# nrf54lilium_network register map
Vendor: Nordic Semiconductor; Series: nrf54; File version: 1
CPU: CM33 r0p4, little endian, MPU, no FPU, 3 interrupt priority bits, 30 interrupts
Registers are 32-bit, read-write, reset 0x0 unless marked. A register's access mark holds for its fields unless they carry their own. Offsets are from the block's base; [hi:lo] are bit positions; {n}, {i} and the like mark numbered series; 'fields as' and 'values as' point back to an identical list.

## RADIO (part 2 of 3) — 2.4 GHz radio 2.4 GHz radio
Base 0x41008000
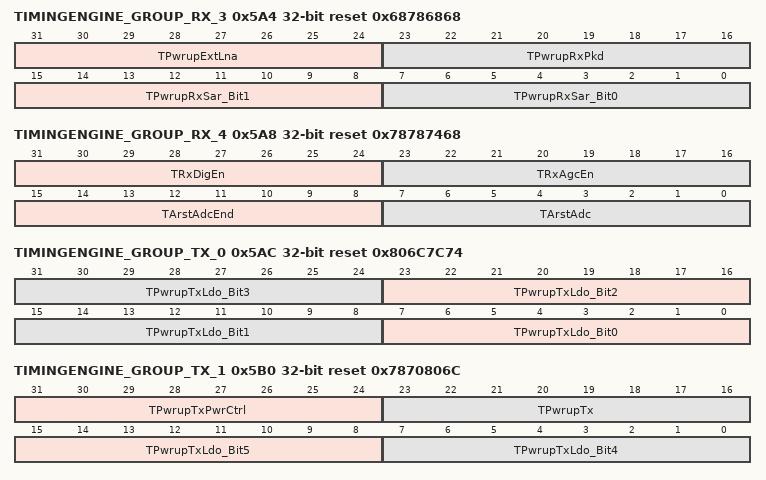
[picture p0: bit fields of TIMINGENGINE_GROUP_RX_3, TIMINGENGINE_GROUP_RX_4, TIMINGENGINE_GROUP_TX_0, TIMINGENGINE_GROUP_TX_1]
0x5A4 TIMINGENGINE_GROUP_RX_3 reset 0x68786868 — TODO
  [31:24] TPwrupExtLna — (unit: 0.25us) Timing control of PwrupExtLna
  [23:16] TPwrupRxPkd — Spare register. Power up peak detector is now tied with power up mixer.
  [15:8] TPwrupRxSar_Bit1 — (unit: 0.25us) Timing control of PwrupRxSar[1]
  [7:0] TPwrupRxSar_Bit0 — (unit: 0.25us) Timing control of PwrupRxSar[0]
0x5A8 TIMINGENGINE_GROUP_RX_4 reset 0x78787468 — TODO
  [31:24] TRxDigEn — (unit: 0.25us) Timing control of RxDigEn
  [23:16] TRxAgcEn — (unit: 0.25us) Timing control of RxAgcEn
  [15:8] TArstAdcEnd — (unit: 0.25us) Timing control of ArstAdcEnd
  [7:0] TArstAdc — (unit: 0.25us) Timing control of ArstAdc
0x5AC TIMINGENGINE_GROUP_TX_0 reset 0x806C7C74 — TODO
  [8n+7:8n] TPwrupTxLdo_Bit{n} (n=0..3) — (unit: 0.25us) Timing control of PwrupTxLdo[{n}]
0x5B0 TIMINGENGINE_GROUP_TX_1 reset 0x7870806C — TODO
  [31:24] TPwrupTxPwrCtrl — (unit: 0.25us) Timing control of PwrupTxPwrCtrl
  [23:16] TPwrupTx — (unit: 0.25us) Timing control of PwrupTx
  [15:8] TPwrupTxLdo_Bit5 — (unit: 0.25us) Timing control of PwrupTxLdo[5]
  [7:0] TPwrupTxLdo_Bit4 — (unit: 0.25us) Timing control of PwrupTxLdo[4]
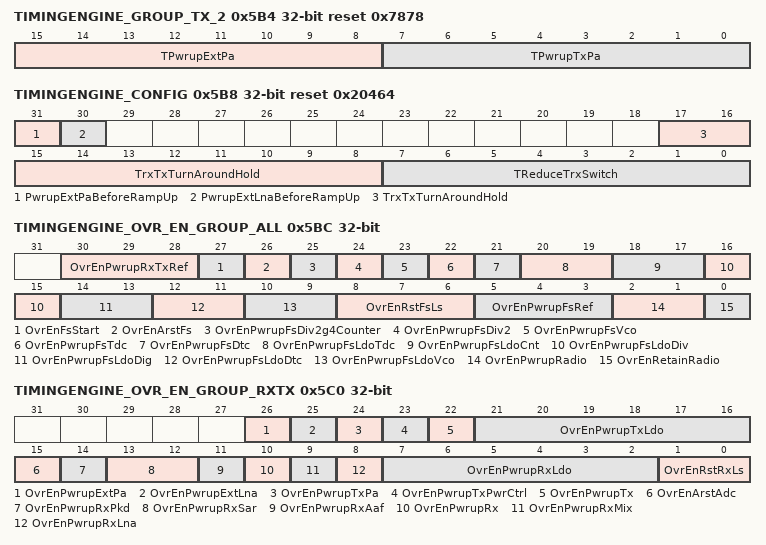
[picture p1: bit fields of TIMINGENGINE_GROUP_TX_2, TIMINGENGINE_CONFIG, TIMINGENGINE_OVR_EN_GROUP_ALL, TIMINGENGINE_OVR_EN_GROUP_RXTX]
0x5B4 TIMINGENGINE_GROUP_TX_2 reset 0x7878 — TODO
  [15:8] TPwrupExtPa — (unit: 0.25us) Timing control of PwrupExtPa
  [7:0] TPwrupTxPa — (unit: 0.25us) Timing control of PwrupTxPa
0x5B8 TIMINGENGINE_CONFIG reset 0x20464 — TODO
  [31] PwrupExtPaBeforeRampUp — In legacy timing mode, pwrupExtPa can be powered on before starting to ramp up by setting this registers to 1.
  [30] PwrupExtLnaBeforeRampUp — In legacy timing mode, pwrupExtLna can be powered on before starting to ramp up by setting this registers to 1.
  [17:8] TrxTxTurnAroundHold — (unit: 0.25us) Additional delay to hold Tx/Rx turnaround
  [7:0] TReduceTrxSwitch — (unit: 0.25us) Reduced timing for on-the-fly switch on both Rx->Tx and Tx->Rx
0x5BC TIMINGENGINE_OVR_EN_GROUP_ALL — TODO
  [30:28] OvrEnPwrupRxTxRef — Override enable of PwrupRxTxRef
  [27] OvrEnFsStart — Override enable of FsStart
  [26] OvrEnArstFs — Override enable of ArstFs
  [25] OvrEnPwrupFsDiv2g4Counter — Override enable of PwrupFsDiv2g4Counter
  [24] OvrEnPwrupFsDiv2 — Override enable of PwrupFsDiv2
  [23] OvrEnPwrupFsVco — Override enable of PwrupFsVco
  [22] OvrEnPwrupFsTdc — Override enable of PwrupFsTdc
  [21] OvrEnPwrupFsDtc — Override enable of PwrupFsDtc
  [20:19] OvrEnPwrupFsLdoTdc — Override enable of PwrupFsLdoTdc
  [18:17] OvrEnPwrupFsLdoCnt — Override enable of PwrupFsLdoCnt
  [16:15] OvrEnPwrupFsLdoDiv — Override enable of PwrupFsLdoDiv
  [14:13] OvrEnPwrupFsLdoDig — Override enable of PwrupFsLdoDig
  [12:11] OvrEnPwrupFsLdoDtc — Override enable of PwrupFsLdoDtc
  [10:9] OvrEnPwrupFsLdoVco — Override enable of PwrupFsLdoVco
  [8:6] OvrEnRstFsLs — Override enable of RstFsLs
  [5:3] OvrEnPwrupFsRef — Override enable of PwrupFsRef
  [2:1] OvrEnPwrupRadio — Override enable of PwrupRadio
  [0] OvrEnRetainRadio — Override enable of RetainRadio
0x5C0 TIMINGENGINE_OVR_EN_GROUP_RXTX — TODO
  [26] OvrEnPwrupExtPa — Override enable of PwrupExtPa
  [25] OvrEnPwrupExtLna — Override enable of PwrupExtLna
  [24] OvrEnPwrupTxPa — Override enable of PwrupTxPa
  [23] OvrEnPwrupTxPwrCtrl — Override enable of PwrupTxPwrCtrl
  [22] OvrEnPwrupTx — Override enable of PwrupTx
  [21:16] OvrEnPwrupTxLdo — Override enable of PwrupTxLdo
  [15] OvrEnArstAdc — Override enable of ArstAdc
  [14] OvrEnPwrupRxPkd — Override enable of PwrupRxPkd
  [13:12] OvrEnPwrupRxSar — Override enable of PwrupRxSar
  [11] OvrEnPwrupRxAaf — Override enable of PwrupRxAaf
  [10] OvrEnPwrupRx — Override enable of PwrupRx
  [9] OvrEnPwrupRxMix — Override enable of PwrupRxMix
  [8] OvrEnPwrupRxLna — Override enable of PwrupRxLna
  [7:2] OvrEnPwrupRxLdo — Override enable of PwrupRxLdo
  [1:0] OvrEnRstRxLs — Override enable of RstRxLs
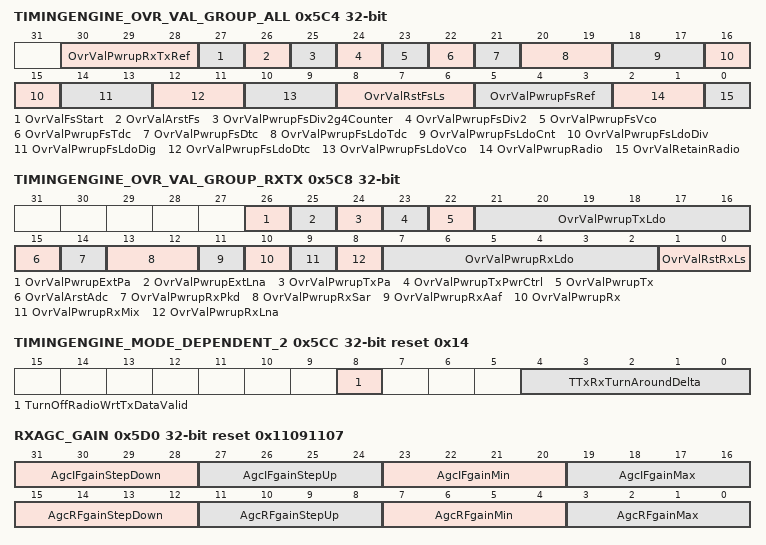
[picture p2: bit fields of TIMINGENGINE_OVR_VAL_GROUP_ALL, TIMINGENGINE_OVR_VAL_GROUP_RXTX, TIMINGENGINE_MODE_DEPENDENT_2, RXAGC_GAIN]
0x5C4 TIMINGENGINE_OVR_VAL_GROUP_ALL — TODO
  [30:28] OvrValPwrupRxTxRef — Override value of PwrupRxTxRef
  [27] OvrValFsStart — Override value of FsStart
  [26] OvrValArstFs — Override value of ArstFs
  [25] OvrValPwrupFsDiv2g4Counter — Override value of PwrupFsDiv2g4Counter
  [24] OvrValPwrupFsDiv2 — Override value of PwrupFsDiv2
  [23] OvrValPwrupFsVco — Override value of PwrupFsVco
  [22] OvrValPwrupFsTdc — Override value of PwrupFsTdc
  [21] OvrValPwrupFsDtc — Override value of PwrupFsDtc
  [20:19] OvrValPwrupFsLdoTdc — Override value of PwrupFsLdoTdc
  [18:17] OvrValPwrupFsLdoCnt — Override value of PwrupFsLdoCnt
  [16:15] OvrValPwrupFsLdoDiv — Override value of PwrupFsLdoDiv
  [14:13] OvrValPwrupFsLdoDig — Override value of PwrupFsLdoDig
  [12:11] OvrValPwrupFsLdoDtc — Override value of PwrupFsLdoDtc
  [10:9] OvrValPwrupFsLdoVco — Override value of PwrupFsLdoVco
  [8:6] OvrValRstFsLs — Override value of RstFsLs
  [5:3] OvrValPwrupFsRef — Override value of PwrupFsRef
  [2:1] OvrValPwrupRadio — Override value of PwrupRadio
  [0] OvrValRetainRadio — Override value of RetainRadio
0x5C8 TIMINGENGINE_OVR_VAL_GROUP_RXTX — TODO
  [26] OvrValPwrupExtPa — Override value of PwrupExtPa
  [25] OvrValPwrupExtLna — Override value of PwrupExtLna
  [24] OvrValPwrupTxPa — Override value of PwrupTxPa
  [23] OvrValPwrupTxPwrCtrl — Override value of PwrupTxPwrCtrl
  [22] OvrValPwrupTx — Override value of PwrupTx
  [21:16] OvrValPwrupTxLdo — Override value of PwrupTxLdo
  [15] OvrValArstAdc — Override value of ArstAdc
  [14] OvrValPwrupRxPkd — Override value of PwrupRxPkd
  [13:12] OvrValPwrupRxSar — Override value of PwrupRxSar
  [11] OvrValPwrupRxAaf — Override value of PwrupRxAaf
  [10] OvrValPwrupRx — Override value of PwrupRx
  [9] OvrValPwrupRxMix — Override value of PwrupRxMix
  [8] OvrValPwrupRxLna — Override value of PwrupRxLna
  [7:2] OvrValPwrupRxLdo — Override value of PwrupRxLdo
  [1:0] OvrValRstRxLs — Override value of RstRxLs
0x5CC TIMINGENGINE_MODE_DEPENDENT_2 reset 0x14 — TODO
  [8] TurnOffRadioWrtTxDataValid — Turn off radio w.r.t txDataValid in addition to radioEn
  [4:0] TTxRxTurnAroundDelta — Additional offset in Rx mode, for Rx to be able to be ready earlier, which is required for 2Mbps.
0x5D0 RXAGC_GAIN reset 0x11091107 — TODO
  [31:28] AgcIFgainStepDown — gain step for decreasing IF gain
  [27:24] AgcIFgainStepUp — gain step for increasing IF gain
  [23:20] AgcIFgainMin — Minimum gain of IF gain
  [19:16] AgcIFgainMax — Maximum gain of IF gain
  [15:12] AgcRFgainStepDown — gain step for decreasing RF gain
  [11:8] AgcRFgainStepUp — gain step for increasing RF gain
  [7:4] AgcRFgainMin — Minimum gain of RF gain
  [3:0] AgcRFgainMax — Maximum gain of RF gain
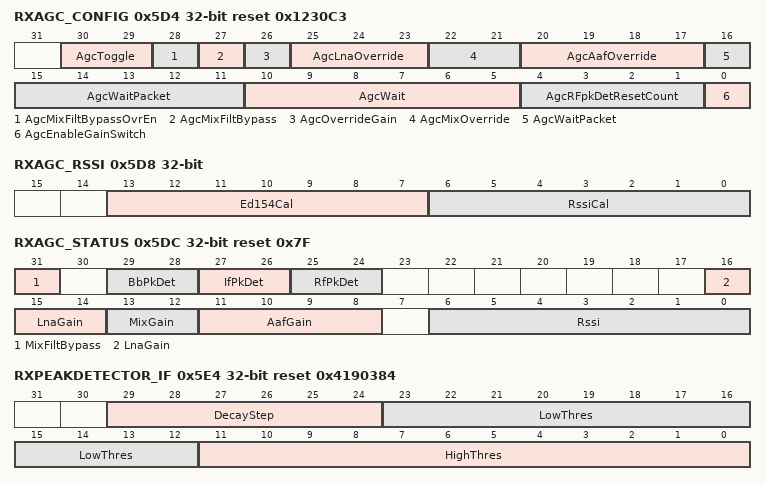
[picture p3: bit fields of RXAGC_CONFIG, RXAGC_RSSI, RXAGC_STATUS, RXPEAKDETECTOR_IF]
0x5D4 RXAGC_CONFIG reset 0x1230C3 — TODO
  [30:29] AgcToggle — Enable(1) or disable(0) functional testmode for AGC
  [28] AgcMixFiltBypassOvrEn — 0: AGC takes control of RC-filter in passive mixer, 1: Control RC-filter in passive mixer from register
  [27] AgcMixFiltBypass — 0: Enable RC-filter in passive mixer, 1: Bypass RC-filter in passive mixer
  [26] AgcOverrideGain — 0: AGC takes control of all gains, 1: Control all gains (aafGain, mixGain, lnaGain) from registers
  [25:23] AgcLnaOverride — Override value for lnaGain
  [22:21] AgcMixOverride — Override value for mixGain
  [20:17] AgcAafOverride — Override value for aafGain
  [16:11] AgcWaitPacket — The number of clock cycles between each adjustment of the gain while addressMatch is high
  [10:5] AgcWait — The number of clock cycles between each adjustment of the gain while addressMatch is low
  [4:1] AgcRFpkDetResetCount — The number of clock cycles after the adjustment of gain that the reset signal to the RF peak detector is set high
  [0] AgcEnableGainSwitch — Causes the RF gain to be decreased and the IF gain to be increased if the overall gain can be maintained
0x5D8 RXAGC_RSSI — TODO
  [13:7] Ed154Cal — 802.15.4 Energy Detect calibration value
  [6:0] RssiCal — RSSI calibration value
0x5DC RXAGC_STATUS ro reset 0x7F — TODO
  [31] MixFiltBypass — MIX RC-filter status
  [29:28] BbPkDet — BB peak detector output. Represent state[1:0] in RxAgc
  [27:26] IfPkDet — IF peak detector output. Represent state[3:2] in RxAgc
  [25:24] RfPkDet — RF peak detector output after sync. Represent state[5:4] in RxAgc
  [16:14] LnaGain — LNA gain status
  [13:12] MixGain — MIX gain status
  [11:8] AafGain — AAF gain status
  [6:0] Rssi — Received signal strength indicator
0x5E0 RXSATURATIONDETECT — TODO
  [3:0] SatDelayCorrection — combination of several PARs in PantherPar
0x5E4 RXPEAKDETECTOR_IF reset 0x4190384 — TODO
  [29:24] DecayStep — TODO
  [23:12] LowThres — Low threshold of IF peak detector. This valued is based on the 11-bits ADC of SPHYNX_ANA
  [11:0] HighThres — High threshold of IF peak detector. This valued is based on the 11-bits ADC of SPHYNX_ANA
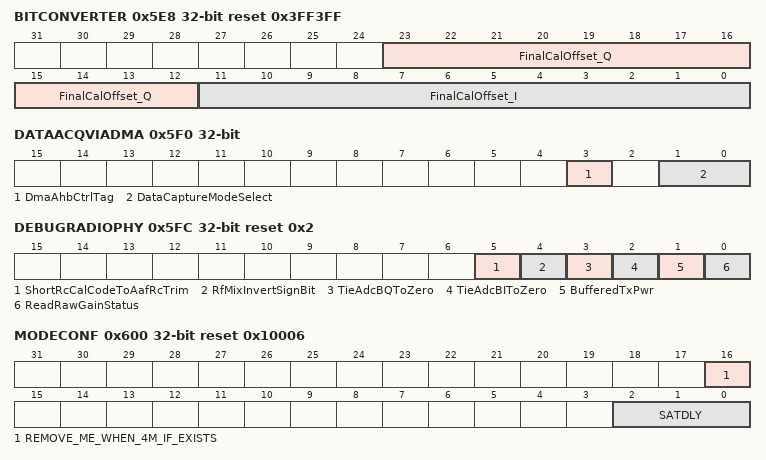
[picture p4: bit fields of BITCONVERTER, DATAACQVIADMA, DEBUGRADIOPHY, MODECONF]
0x5E8 BITCONVERTER reset 0x3FF3FF — TODO
  [23:12] FinalCalOffset_Q — ADC offset compensation of channel Q. (signed)
  [11:0] FinalCalOffset_I — ADC offset compensation of channel I. (signed)
0x5F0 DATAACQVIADMA — TODO
  [3] DmaAhbCtrlTag — used to be NrfModem port - dmaAhbCtrlTag, selection of DMA in radio. MUX(Panther/UTxRxChain)
  [1:0] DataCaptureModeSelect — Which of 4 existing mode it is running (each mode correspond the a particular set of data to be logged)
0x5FC DEBUGRADIOPHY reset 0x2 — TODO
  [5] ShortRcCalCodeToAafRcTrim — 1: short RCCAL_CODE[3:0] to RX_AAF_RCTRIMM[3:0]
  [4] RfMixInvertSignBit — 1: Invert the sign bit of calibration code for DC offset calibration(invert DCCAL[4]). This inverts both channel I and Q.
  [3] TieAdcBQToZero — 0: output normal adcBinaryBQ, 1: tie adcBinaryBQ to zero
  [2] TieAdcBIToZero — 0: output normal adcBinaryBI, 1: tie adcBinaryBI to zero
  [1] BufferedTxPwr — Set to high to buffer TXPOWER so that sub-modules in the MMI will only update next tx power config at TX_EN, RX_EN and LB_EN. Set to low if special test is needed for Tx test.
  [0] ReadRawGainStatus — 0: readout latched gain values from RXAGC_STATUS, 1: readout raw gain values from RXAGC_STATUS
0x600 MODECONF reset 0x10006 — IQCal status
  [16] REMOVE_ME_WHEN_4M_IF_EXISTS — temporary 4Mbps special case signal for mixer
  [2:0] SATDLY — Mode dependent register with saturation delay for different modes
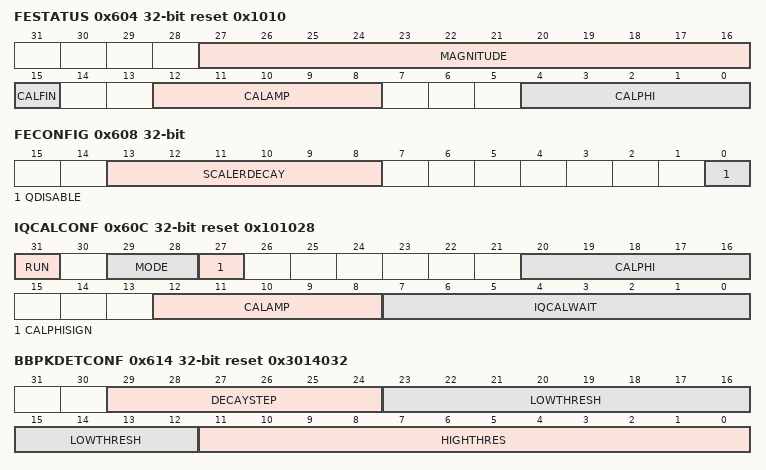
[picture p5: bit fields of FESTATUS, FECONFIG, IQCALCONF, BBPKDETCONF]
0x604 FESTATUS ro reset 0x1010 — Frontend readout register
  [27:16] MAGNITUDE — Magnitude output from BB peak detector
  [15] CALFIN — High when IQCal search finished
  [12:8] CALAMP — calAmp from IQCal
  [4:0] CALPHI — calPhi from IQCal
0x608 FECONFIG — Config for Mixer and Scaler
  [13:8] SCALERDECAY — The number of clock cycles to wait before stepping down the internal memory for the scaling. The value 0 means that the decay feature is off.
  [0] QDISABLE — Disable Q samples to save power
0x60C IQCALCONF reset 0x101028 — Gain and phase mismatch calibration control for I and Q
  [31] RUN — Run I and Q calibration procedure
    0=Stored (Using stored values for calPhi and calAmp); 1=Calib (Running calibration.)
  [29:28] MODE — IQCal search mode
    0=Optimized search algorithm; 1=Exhaustive search; 2=Cancellation (Optimized search with cancellation.)
  [27] CALPHISIGN — Sign of calPhi value
  [20:16] CALPHI — Stored calPhi value
  [12:8] CALAMP — Stored calAmp value
  [7:0] IQCALWAIT — Settling time (in number of 16 MHz clock periods) for rssi input to stabilize
0x610 LOGMAG reset 0x500 — IQCal status
  [15:8] ALPHA — Alpha for IIR filter used in logMag calculation
0x614 BBPKDETCONF reset 0x3014032 — Configuration for baseband peak detector
  [29:24] DECAYSTEP — Constant output reduction step
  [23:12] LOWTHRESH — Low threshold for peak detector
  [11:0] HIGHTHRES — High threshold for peak detector
0x618 OUTMAIN_CKSEL_DECFIR reset 0x2 — Clock select register for the output outMain
  [2:0] CKSEL — Number of times to divide the base clock rate by 2. Exception: highest value gives BYPASS, ie. clock is disabled and data out is assigned directly from data in.
    0=ClkSel_32M (CKSEL_32M); 1=ClkSel_16M (CKSEL_16M); 2=ClkSel_8M (CKSEL_8M); 3=ClkSel_4M (CKSEL_4M); 4=ClkSel_2M (CKSEL_2M); 5=ClkSel_1M (CKSEL_1M); 6=ClkSel_500K (CKSEL_500K); 7=ClkSel_Bypass (CKSEL_BYPASS)
0x61C DECFIR0_CKSEL reset 0x7 — Clock select register for the PUnit decFIR0 of type IP_FIR
  [2:0] CKSEL — Number of times to divide the base clock rate by 2. Exception: highest value gives BYPASS, ie. clock is disabled and data out is assigned directly from data in.
    0=ClkSel_32M (CKSEL_32M); 1=ClkSel_16M (CKSEL_16M); 2=ClkSel_8M (CKSEL_8M); 3=ClkSel_4M (CKSEL_4M); 4=ClkSel_2M (CKSEL_2M); 5=ClkSel_1M (CKSEL_1M); 6=ClkSel_500k (CKSEL_500K); 7=ClkSel_Bypass (CKSEL_BYPASS)
0x620 DECFIR0_CONTROL reset 0x2 — Control register for the PUnit decFIR0 of type IP_FIR
  [1:0] TAPSEL — Tap-select: number of active taps minus 2
0x624 DECFIR0_COEFFS_0 reset 0x4 — Coefficient register 0 for the PUnit decFIR0 of type IP_FIR
  [3:0] COEFFS_0 — Signed filter coefficient 0
0x628 DECFIR0_COEFFS_1 reset 0x6 — Coefficient register 1 for the PUnit decFIR0 of type IP_FIR
  [3:0] COEFFS_1 — Signed filter coefficient 1
0x62C DECFIR0_COEFFS_2 reset 0x6 — Coefficient register 2 for the PUnit decFIR0 of type IP_FIR
  [3:0] COEFFS_2 — Signed filter coefficient 2
0x630 DECFIR0_COEFFS_3 — Coefficient register 3 for the PUnit decFIR0 of type IP_FIR
  [3:0] COEFFS_3 — Signed filter coefficient 3
0x634 DECFIR1_CKSEL — Clock select register for the PUnit decFIR1 of type IP_FIR
  fields as OUTMAIN_CKSEL_DECFIR
0x638 DECFIR1_CONTROL reset 0x4 — Control register for the PUnit decFIR1 of type IP_FIR
  [2:0] TAPSEL — Tap-select: number of active taps minus 2
0x63C DECFIR1_COEFFS_0 reset 0x8 — Coefficient register 0 for the PUnit decFIR1 of type IP_FIR
  [5:0] COEFFS_0 — Signed filter coefficient 0
0x640 DECFIR1_COEFFS_1 reset 0x10 — Coefficient register 1 for the PUnit decFIR1 of type IP_FIR
  [5:0] COEFFS_1 — Signed filter coefficient 1
0x644 DECFIR1_COEFFS_2 reset 0x18 — Coefficient register 2 for the PUnit decFIR1 of type IP_FIR
  [5:0] COEFFS_2 — Signed filter coefficient 2
0x648 DECFIR1_COEFFS_3 reset 0x10 — Coefficient register 3 for the PUnit decFIR1 of type IP_FIR
  [5:0] COEFFS_3 — Signed filter coefficient 3
0x64C DECFIR1_COEFFS_4 — Coefficient register 4 for the PUnit decFIR1 of type IP_FIR
  [5:0] COEFFS_4 — Signed filter coefficient 4
0x650 DECFIR1_COEFFS_5 — Coefficient register 5 for the PUnit decFIR1 of type IP_FIR
  [5:0] COEFFS_5 — Signed filter coefficient 5
0x654 DECFIR2_CKSEL reset 0x1 — Clock select register for the PUnit decFIR2 of type IP_FIR
  fields as OUTMAIN_CKSEL_DECFIR
0x658 DECFIR2_CONTROL reset 0x4 — Control register for the PUnit decFIR2 of type IP_FIR
  [2:0] TAPSEL — Tap-select: number of active taps minus 2
0x65C DECFIR2_COEFFS_0 reset 0x8 — Coefficient register 0 for the PUnit decFIR2 of type IP_FIR
  [5:0] COEFFS_0 — Signed filter coefficient 0
0x660 DECFIR2_COEFFS_1 reset 0x10 — Coefficient register 1 for the PUnit decFIR2 of type IP_FIR
  [5:0] COEFFS_1 — Signed filter coefficient 1
0x664 DECFIR2_COEFFS_2 reset 0x18 — Coefficient register 2 for the PUnit decFIR2 of type IP_FIR
  [5:0] COEFFS_2 — Signed filter coefficient 2
0x668 DECFIR2_COEFFS_3 reset 0x10 — Coefficient register 3 for the PUnit decFIR2 of type IP_FIR
  [5:0] COEFFS_3 — Signed filter coefficient 3
0x66C DECFIR2_COEFFS_4 — Coefficient register 4 for the PUnit decFIR2 of type IP_FIR
  [5:0] COEFFS_4 — Signed filter coefficient 4
0x670 DECFIR2_COEFFS_5 — Coefficient register 5 for the PUnit decFIR2 of type IP_FIR
  [5:0] COEFFS_5 — Signed filter coefficient 5
0x674 OUTMAIN_CKSEL_IIR reset 0x2 — Clock select register for the output outMain
  fields as OUTMAIN_CKSEL_DECFIR
0x678 OUTMAIN_SOURCE reset 0x4 — Source select register for the output outMain
  [3:0] SOURCE — Data source select
    0=SRC_IIR0 (NOT LEGAL); 1=SRC_IIR1 (NOT LEGAL); 2=SRC_NOTCHIIR0 (NOT LEGAL); 3=Src_NotChIIR1; 4=Src_DecFIR; 15=SRC_INMAIN (NOT LEGAL)
0x67C OUTPEAKDET_CKSEL reset 0x2 — Clock select register for the output outPeakDet
  fields as OUTMAIN_CKSEL_DECFIR
0x680 OUTPEAKDET_SOURCE reset 0x3 — Source select register for the output outPeakDet
  fields as OUTMAIN_SOURCE
0x684 IIR0_CKSEL reset 0x2 — Clock select register for the PUnit IIR0 of type IP_IIR2
  fields as OUTMAIN_CKSEL_DECFIR
0x688 IIR0_STATUS write-1-clears — Status register for the PUnit IIR0 of type IP_IIR2
  [1:0] SATURATION_IQ — Saturation status for I/Q (bit 0/1) component (bitwise write 1 to clear)
0x68C IIR0_COEFFS_B0 reset 0x20 — Coefficient register B0 for the PUnit IIR0 of type IP_IIR2
  [9:0] COEFFS_B0 — Signed filter coefficient B0
0x690 IIR0_COEFFS_B1 reset 0x20 — Coefficient register B1 for the PUnit IIR0 of type IP_IIR2
  [9:0] COEFFS_B1 — Signed filter coefficient B1
0x694 IIR0_COEFFS_B2 — Coefficient register B2 for the PUnit IIR0 of type IP_IIR2
  [9:0] COEFFS_B2 — Signed filter coefficient B2
0x698 IIR0_COEFFS_A1 reset 0x340 — Coefficient register A1 for the PUnit IIR0 of type IP_IIR2
  [9:0] COEFFS_A1 — Signed filter coefficient A1
0x69C IIR0_COEFFS_A2 — Coefficient register A2 for the PUnit IIR0 of type IP_IIR2
  [9:0] COEFFS_A2 — Signed filter coefficient A2
0x6A0 IIR1_CKSEL reset 0x2 — Clock select register for the PUnit IIR1 of type IP_IIR2
  fields as OUTMAIN_CKSEL_DECFIR
0x6A4 IIR1_STATUS write-1-clears — Status register for the PUnit IIR1 of type IP_IIR2
  fields as IIR0_STATUS
{0x6A8+4i} IIR1_COEFFS_B{i} reset 0x6 (i=0..2) — Coefficient register B{i} for the PUnit IIR1 of type IP_IIR2
  [8:0] COEFFS_B{i} — Signed filter coefficient B{i}
0x6B4 IIR1_COEFFS_A1 reset 0x1A0 — Coefficient register A1 for the PUnit IIR1 of type IP_IIR2
  [8:0] COEFFS_A1 — Signed filter coefficient A1
0x6B8 IIR1_COEFFS_A2 reset 0x30 — Coefficient register A2 for the PUnit IIR1 of type IP_IIR2
  [8:0] COEFFS_A2 — Signed filter coefficient A2
0x6BC NOTCHIIR0_CKSEL reset 0x2 — Clock select register for the PUnit notchIIR0 of type IP_IIR2
  fields as OUTMAIN_CKSEL_DECFIR
0x6C0 NOTCHIIR0_SOURCE reset 0x1 — Source select register for the PUnit notchIIR0 of type IP_IIR2
  fields as OUTMAIN_SOURCE
0x6C4 NOTCHIIR0_STATUS write-1-clears — Status register for the PUnit notchIIR0 of type IP_IIR2
  fields as IIR0_STATUS
0x6C8 NOTCHIIR0_COEFFS_B0 reset 0x78 — Coefficient register B0 for the PUnit notchIIR0 of type IP_IIR2
  [8:0] COEFFS_B0 — Signed filter coefficient B0
0x6CC NOTCHIIR0_COEFFS_B1 reset 0x156 — Coefficient register B1 for the PUnit notchIIR0 of type IP_IIR2
  [8:0] COEFFS_B1 — Signed filter coefficient B1
0x6D0 NOTCHIIR0_COEFFS_B2 reset 0x78 — Coefficient register B2 for the PUnit notchIIR0 of type IP_IIR2
  [8:0] COEFFS_B2 — Signed filter coefficient B2
0x6D4 NOTCHIIR0_COEFFS_A1 reset 0x156 — Coefficient register A1 for the PUnit notchIIR0 of type IP_IIR2
  [8:0] COEFFS_A1 — Signed filter coefficient A1
0x6D8 NOTCHIIR0_COEFFS_A2 reset 0x70 — Coefficient register A2 for the PUnit notchIIR0 of type IP_IIR2
  [8:0] COEFFS_A2 — Signed filter coefficient A2
0x6DC NOTCHIIR1_CKSEL reset 0x7 — Clock select register for the PUnit notchIIR1 of type IP_IIR2
  fields as OUTMAIN_CKSEL_DECFIR
0x6E0 NOTCHIIR1_STATUS write-1-clears — Status register for the PUnit notchIIR1 of type IP_IIR2
  fields as IIR0_STATUS
{0x6E4+4i} NOTCHIIR1_COEFFS_B{i} (i=0..2) — Coefficient register B{i} for the PUnit notchIIR1 of type IP_IIR2
  [7:0] COEFFS_B{i} — Signed filter coefficient B{i}
0x6F0 NOTCHIIR1_COEFFS_A1 — Coefficient register A1 for the PUnit notchIIR1 of type IP_IIR2
  [7:0] COEFFS_A1 — Signed filter coefficient A1
0x6F4 NOTCHIIR1_COEFFS_A2 — Coefficient register A2 for the PUnit notchIIR1 of type IP_IIR2
  [7:0] COEFFS_A2 — Signed filter coefficient A2
0x6F8 DECFIR_CKSEL reset 0x7 — Clock select register for the PUnit decFIR of type IP_FIR
  fields as OUTMAIN_CKSEL_DECFIR
0x6FC DECFIR_SOURCE reset 0x3 — Source select register for the PUnit decFIR of type IP_FIR
  fields as OUTMAIN_SOURCE
0x700 DECFIR_CONTROL reset 0x4 — Control register for the PUnit decFIR of type IP_FIR
  [2:0] TAPSEL — Tap-select: number of active taps minus 2
0x704 DECFIR_COEFFS_0 reset 0x8 — Coefficient register 0 for the PUnit decFIR of type IP_FIR
  [5:0] COEFFS_0 — Signed filter coefficient 0
0x708 DECFIR_COEFFS_1 reset 0x10 — Coefficient register 1 for the PUnit decFIR of type IP_FIR
  [5:0] COEFFS_1 — Signed filter coefficient 1
0x70C DECFIR_COEFFS_2 reset 0x18 — Coefficient register 2 for the PUnit decFIR of type IP_FIR
  [5:0] COEFFS_2 — Signed filter coefficient 2
0x710 DECFIR_COEFFS_3 reset 0x10 — Coefficient register 3 for the PUnit decFIR of type IP_FIR
  [5:0] COEFFS_3 — Signed filter coefficient 3
0x714 DECFIR_COEFFS_4 — Coefficient register 4 for the PUnit decFIR of type IP_FIR
  [5:0] COEFFS_4 — Signed filter coefficient 4
0x718 DECFIR_COEFFS_5 — Coefficient register 5 for the PUnit decFIR of type IP_FIR
  [5:0] COEFFS_5 — Signed filter coefficient 5
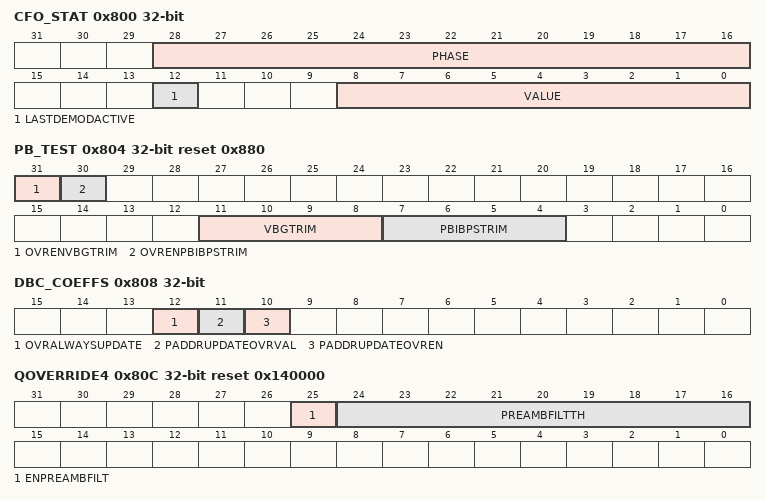
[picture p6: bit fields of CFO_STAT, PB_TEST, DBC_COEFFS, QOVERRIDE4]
0x800 CFO_STAT ro — Carrier freq. offset estimate
  [28:16] PHASE — Readout of last valid phase set in correlator (hypermode only) (signed)
  [12] LASTDEMODACTIVE — 0: Standard mode was used last 1: Hypermode was last used
  [8:0] VALUE — Readout of last valid decision level set in BitSlicer (signed)
0x804 PB_TEST reset 0x880 — Test: PB calibration
  [31] OVRENVBGTRIM — if '1' enable override for VBGTRIM
  [30] OVRENPBIBPSTRIM — if '1' enable override for PBIBPSTRIM
  [11:8] VBGTRIM — Trim code for VBG to FS_VCOREG
  [7:4] PBIBPSTRIM — Trim code for IBPS currents
0x808 DBC_COEFFS — Test and Debug: DBC coefficients override
  [12] OVRALWAYSUPDATE — Zero means coefficients only updated when needed (default), set to 1 coefficients are always updated when the radio is enabled.
  [11] PADDRUPDATEOVRVAL
  [10] PADDRUPDATEOVREN
0x80C QOVERRIDE4 reset 0x140000 — Trim value override register 4 for nRF52
  [25] ENPREAMBFILT — Enable preamble filter
  [24:16] PREAMBFILTTH — Threshold for the preamble filter
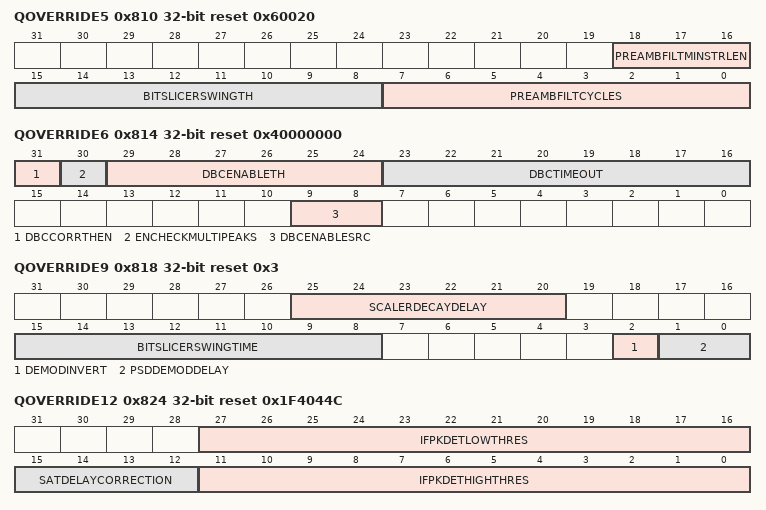
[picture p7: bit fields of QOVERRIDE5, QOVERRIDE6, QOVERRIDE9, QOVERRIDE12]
0x810 QOVERRIDE5 reset 0x60020 — Trim value override register 5 for nRF52
  [18:16] PREAMBFILTMINSTRLEN — Override value for preambFiltMinStrLen
  [15:8] BITSLICERSWINGTH — Override value for bitSlicerSwingTh
  [7:0] PREAMBFILTCYCLES — Override value for preambFiltCycles
0x814 QOVERRIDE6 reset 0x40000000 — Trim value override register 6 for nRF52
  [31] DBCCORRTHEN — Override value enable for DBCCORRTH and MFBSTRBOFFSET
  [30] ENCHECKMULTIPEAKS — Enable checking of several correlator peaks in hypermode
  [29:24] DBCENABLETH — Override value for correlator enable threshold
  [23:16] DBCTIMEOUT — Override value for correlator timeout,in bit periods (hypermode)
  [9:8] DBCENABLESRC — Override value for dbcEnableSrc
    0=Always on when not address match; 1=BBLogMag (When bbLogMag is above a threshold); 2=BitSlicerSwing (When a certain time has gone since the input to the bitslicer was above BITSLICERSWINGTH); 3=Both BBLogMag and BitSlicerSwing
0x818 QOVERRIDE9 reset 0x3 — Trim value override register 9 for nRF52
  [25:20] SCALERDECAYDELAY — Decay delay for the IQ scaler
  [15:8] BITSLICERSWINGTIME
  [2] DEMODINVERT — Override value for demodInvert (standard and hyper)
  [1:0] PSDDEMODDELAY — Override value for psdDemodDelay (standard mode)
0x824 QOVERRIDE12 reset 0x1F4044C — Trim value override register 12 for nRF52
  [27:16] IFPKDETLOWTHRES — Override value for IfpkDetLowThres
  [15:12] SATDELAYCORRECTION — Signed correction value for how much the saturation information is delayed from the input ADC samples to the samples being stored to RAM in direction finding operation
  [11:0] IFPKDETHIGHTHRES — Override value for IfpkDetHighThres
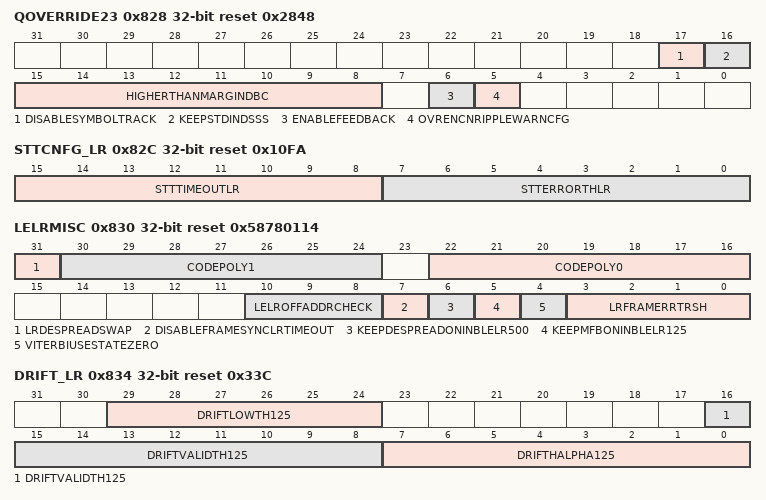
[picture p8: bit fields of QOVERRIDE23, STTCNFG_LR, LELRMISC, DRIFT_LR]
0x828 QOVERRIDE23 reset 0x2848 — Trim value override register 23 for nRF52
  [17] DISABLESYMBOLTRACK — Disable symbol tracking for IEEE 802.15.4 and BLE LR modes
  [16] KEEPSTDINDSSS — Keep standard demod in DSSS mode
  [15:8] HIGHERTHANMARGINDBC — Required peak height required for a double correlator peak to be considered higher than previous ones. The register value will be multiplied by 25 to obtain the actual margin. The bitfield is NOT subject to the enable override at bit position 31, and will always be enabled for hypermode.
  [6] ENABLEFEEDBACK — Enable decision feedback for matched filter bank
  [5] OVRENCNRIPPLEWARNCFG — Override enable for CNPEAKMINTHR and CNABSMAXTHR in the CNRIPPLEWARNCFG register
0x82C STTCNFG_LR reset 0x10FA — Strobe time tracking configuration in long range mode
  [15:8] STTTIMEOUTLR — Strobe time tracking timeout in BLE LR mode
  [7:0] STTERRORTHLR — Strobe time tracking error threshold in BLE LR mode
0x830 LELRMISC reset 0x58780114 — Miscellaneous Controls for Long Range
  [31] LRDESPREADSWAP — Swap de-spreader
  [30:24] CODEPOLY1 — Code Polynom 1
  [22:16] CODEPOLY0 — Code Polynom 0
  [10:8] LELROFFADDRCHECK — The number of chip periods earlier which it is allowed to declare frameSync in DecodeLELong
  [7] DISABLEFRAMESYNCLRTIMEOUT — Disable framesync timeout (early address match timeout) for BLE LR mode (hypermode).
  [6] KEEPDESPREADONINBLELR500 — Do not stop the clock to the Despreader in BLE LR 500 mode
  [5] KEEPMFBONINBLELR125 — Do not stop the clock to RxMFB in BLE LR 125 mode
  [4] VITERBIUSESTATEZERO — Use Viterbi state zero when flushing out bits for BLE LR
  [3:0] LRFRAMERRTRSH — Framer Receive Threshold
0x834 DRIFT_LR reset 0x33C — Drift Controls in Long Range
  [29:24] DRIFTLOWTH125 — Override value for driftLowTh, drift estimator (despreadLELLong)
  [16:8] DRIFTVALIDTH125 — Override value for driftValidTh, drift estimator (despreadLELLong)
  [7:0] DRIFTHALPHA125 — Override value for IIR feedback , drift estimator (despreadLELLong)
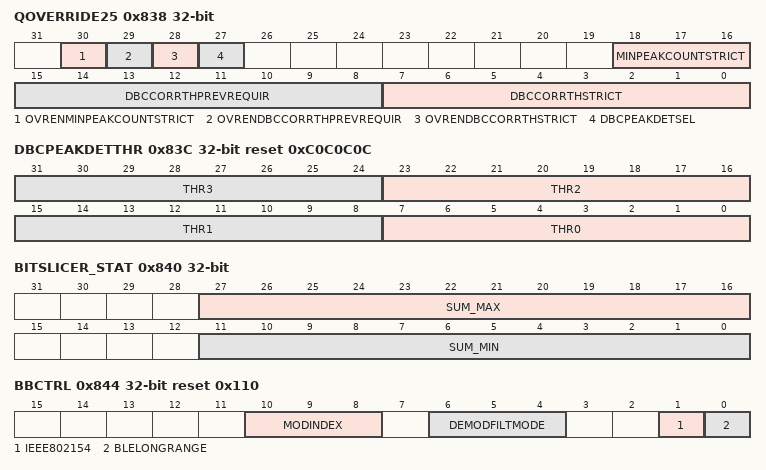
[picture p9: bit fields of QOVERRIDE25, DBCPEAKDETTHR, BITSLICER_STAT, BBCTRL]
0x838 QOVERRIDE25 — TODO
  [30] OVRENMINPEAKCOUNTSTRICT — Override enable for MINPEAKCOUNTSTRICT
  [29] OVRENDBCCORRTHPREVREQUIR — Override enable for DBCCORRTHPREVREQUIR
  [28] OVRENDBCCORRTHSTRICT — Override enable for DBCCORRTHSTRICT
  [27] DBCPEAKDETSEL — DBC peak detector selection
    0=Classic (Use classic peak detector (backward compatible behavior)); 1=Differential (Use differential peak detector)
  [18:16] MINPEAKCOUNTSTRICT — Min number of peaks to detect before resyncing to another preamble while already working on a previous preamble in BleLrx.
  [15:8] DBCCORRTHPREVREQUIR — Correlation threshold for double correlator used in BleLr mode to reject a later resync using DBCCORRTHSTRICT.
  [7:0] DBCCORRTHSTRICT — Correlation threshold for double correlator used in BleLr mode to resync to another preamble while already working on a previous preamble.
0x83C DBCPEAKDETTHR reset 0xC0C0C0C — Thresholds for each peak detector instance
  [8n+7:8n] THR{n} (n=0..3) — Diff threshold {n}
0x840 BITSLICER_STAT ro — Payload status
  [27:16] SUM_MAX — Number of received ones
  [11:0] SUM_MIN — Number of received zeros
0x844 BBCTRL reset 0x110 — Miscellaneous mode bits
  [10:8] MODINDEX — Modulation index for RxDBCCoeffGen and RxMFB
    0=ModIndex_0h25; 1=ModIndex_0h32; 2=ModIndex_0h5; 3=ModIndex_1h0; 4=ModIndex_2h0
  [6:4] DEMODFILTMODE — Decimation mode in PantherDemodFilt
    0=Decimation_2M (DEMODFILTMODE_2M); 1=Decimation_1M (DEMODFILTMODE_1M); 3=Decimation_250K (DEMODFILTMODE_250K)
  [1] IEEE802154 — Enable 15.4 mode (enabling both 15.4 and long range is not legal)
    0=Disable (IEEE802154_NO); 1=Enable (IEEE802154_YES)
  [0] BLELONGRANGE — Enable long range mode (enabling both 15.4 and long range is not legal)
    0=Disable (BLELONGRANGE_NO); 1=Enable (BLELONGRANGE_YES)
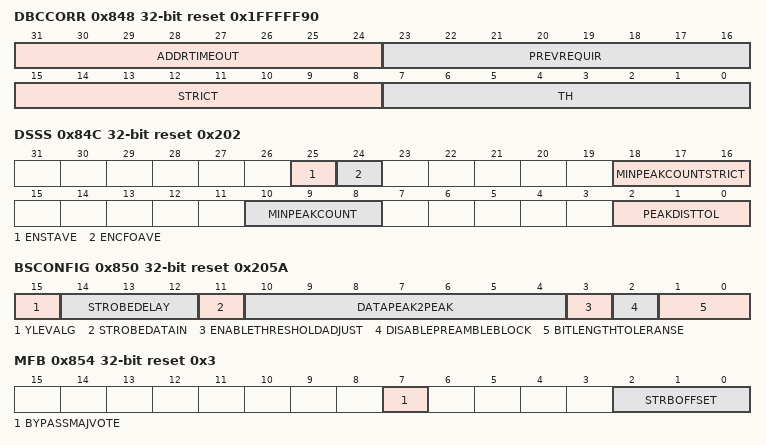
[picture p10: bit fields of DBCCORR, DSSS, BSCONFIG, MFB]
0x848 DBCCORR reset 0x1FFFFF90 — Thresholds for the double correlator
  [31:24] ADDRTIMEOUT — Override value for address match timeout, [in bit periods] (hypermode). 0 means no timeout. If BALEN is 3, the actual value of DBCADDRTIMEOUT will be the value written to this register minus 8.
  [23:16] PREVREQUIR — Correlation threshold for double correlator used in BleLr mode to reject a later resync using DBCCORRTHSTRICT. Also applies for Ieee 802.15.4 mode
  [15:8] STRICT — Correlation threshold for double correlator used in BleLr mode to resync to another preamble while already working on a previous preamble. Also applies for Ieee 802.15.4 mode
  [7:0] TH — Correlation threshold for double correlator in normal operation
0x84C DSSS reset 0x202 — DSSS synchronizer trim values
  [25] ENSTAVE — Enable strobe time averaging
  [24] ENCFOAVE — Enable CFO averaging
  [18:16] MINPEAKCOUNTSTRICT — Min number of peaks to detect before resyncing to another preamble while already working on a previous preamble in BleLrx. Also applies for Ieee 802.15.4 mode
  [10:8] MINPEAKCOUNT — Override for dsssMinPeakCount
  [2:0] PEAKDISTTOL — Override for dsssPeakDistanceTolerance
0x850 BSCONFIG reset 0x205A — Bitslicer configuration
  [15] YLEVALG — Override for bsYlevAlg
  [14:12] STROBEDELAY — Override for bsStrobeDelay
  [11] STROBEDATAIN — Override for bsStrobeDataIn
  [10:4] DATAPEAK2PEAK — Override for bsDataPeak2Peak
  [3] ENABLETHRESHOLDADJUST — Override for bsEnableThresholdAdjust
  [2] DISABLEPREAMBLEBLOCK — Override for bsDisablePreambleBlock
  [1:0] BITLENGTHTOLERANSE — Override for bsBitLengthToleranse
0x854 MFB reset 0x3 — Matched Filter Bank (MFB) configuration
  [7] BYPASSMAJVOTE — Bypass majority vote
    0=PASS (Majority vite); 1=BYPASS (Bypass through majority vote)
  [2:0] STRBOFFSET — Override value for strobe offset
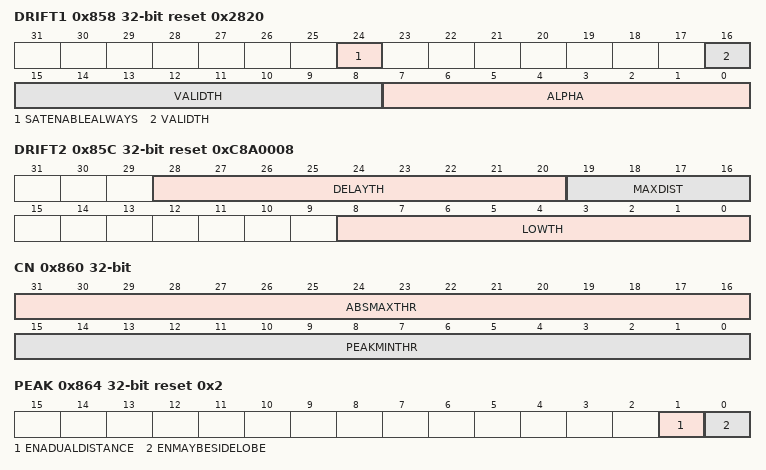
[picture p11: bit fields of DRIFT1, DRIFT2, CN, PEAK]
0x858 DRIFT1 reset 0x2820 — Drift Estimator configuration
  [24] SATENABLEALWAYS — Enable saturation in drift calculator for all modes
  [16:8] VALIDTH — Override value for driftValidTh, drift estimator (hypermode)
  [7:0] ALPHA — Override value for IIR feedback , drift estimator (hypermode)
0x85C DRIFT2 reset 0xC8A0008 — Drift Estimator configuration
  [28:20] DELAYTH — Override value for driftDelayTh, drift estimator (hypermode)
  [19:16] MAXDIST — Override value for driftMaxDist, drift estimator (hypermode)
  [8:0] LOWTH — Override value for driftLowTh, drift estimator (hypermode)
0x860 CN — Configuration for the CNRIPPLEWARN functionality used for BLE LR. Configuration is only enabled when OVRENCNRIPPLEWARNCFG in OVERRIDE23 is set
  [31:16] ABSMAXTHR — maximum baseline value before the peak at the double correlator output. if the baseline value is above the threshold, the following peak will be ignored. this value is ignored when CNABSMAXTHR is set to 0x0000.
  [15:0] PEAKMINTHR — Required peak height compared to baseline level measured just before the peak at the double correlator output. If the peak height is below the threshold, it will be ignored. This feature is disabled when CNPEAKMINTHR is set to 0x0000.
0x864 PEAK reset 0x2 — Peak detector configuration
  [1] ENADUALDISTANCE — Allow dual distance between peaks
  [0] ENMAYBESIDELOBE — Ignore peaks from DBC which look like sidelobes
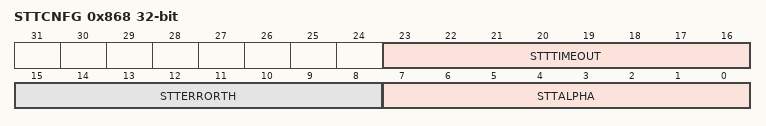
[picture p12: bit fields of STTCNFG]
0x868 STTCNFG — Strobe time tracking Configuration (Symbol Timing)
  [23:16] STTTIMEOUT — Strobe time tracking: adjustment timeout (min distance in symbolperiods between strobe adjustments in same direction)
  [15:8] STTERRORTH — Strobe time tracking: strobe time error threshold
  [7:0] STTALPHA — Strobe time tracking: IIR filter alpha
